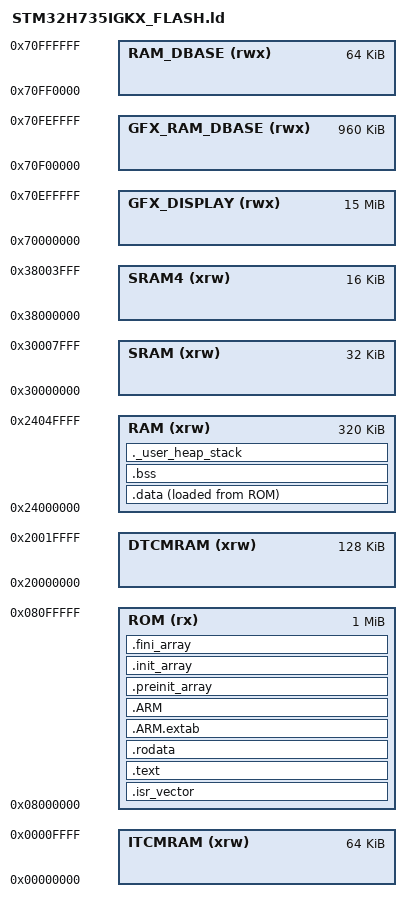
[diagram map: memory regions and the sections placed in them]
/**
 ******************************************************************************
 * @file      LinkerScript.ld
 * @author    Auto-generated by STM32CubeIDE
 *  Abstract    : Linker script for STM32H735G-DK Board embedding STM32H735IGKx Device from stm32h7 series
 *                      1024Kbytes ROM
 *                      64Kbytes ITCMRAM
 *                      128Kbytes RAM
 *
 *            Set heap size, stack size and stack location according
 *            to application requirements.
 *
 *            Set memory bank area and size if external memory is used
 ******************************************************************************
 * @attention
 *
 * Copyright (c) 2020 STMicroelectronics.
 * All rights reserved.
 *
 * This software is licensed under terms that can be found in the LICENSE file
 * in the root directory of this software component.
 * If no LICENSE file comes with this software, it is provided AS-IS.
 *
 ******************************************************************************
 */

/* Entry Point */
ENTRY(Reset_Handler)

/* Generate a link error if heap and stack don't fit into RAM */

_Min_Heap_Size  = __HEAP_SIZE;    /* required amount of heap  */
_Min_Stack_Size = __STACK_SIZE;   /* required amount of stack */

/* Specify the memory areas */
MEMORY
{
    ROM              (rx)  : ORIGIN = 0x08000000, LENGTH = 1024K
    ITCMRAM          (xrw) : ORIGIN = 0x00000000, LENGTH = 64K
    DTCMRAM          (xrw) : ORIGIN = 0x20000000, LENGTH = 128K
    RAM              (xrw) : ORIGIN = 0x24000000, LENGTH = 320K             /* Combine AXI SRAM and RAM Shared ITCM and AXI */
    SRAM             (xrw) : ORIGIN = 0x30000000, LENGTH = 32K              /* Combine SRAM1 and SRAM2 */
    SRAM4            (xrw) : ORIGIN = 0x38000000, LENGTH = 16K
    GFX_DISPLAY      (rwx) : ORIGIN = 0x70000000, LENGTH = 15M
    GFX_RAM_DBASE    (rwx) : ORIGIN = ORIGIN(GFX_DISPLAY) + LENGTH(GFX_DISPLAY), LENGTH = 1M - 64K
    RAM_DBASE        (rwx) : ORIGIN = ORIGIN(GFX_RAM_DBASE) + LENGTH(GFX_RAM_DBASE), LENGTH = 64K
}

/* Highest address of the user mode stack */
_estack = ORIGIN(RAM) + LENGTH(RAM);
_StackBottom = _estack - __STACK_SIZE;

/* Define output sections */
SECTIONS
{
  /* The startup code goes first into ROM */
  .isr_vector :
  {
    . = ALIGN(4);
    KEEP(*(.isr_vector)) /* Startup code */
    . = ALIGN(4);
  } >ROM

  /* The program code and other data into "ROM" Rom type memory */
  .text :
  {
    . = ALIGN(4);
    *(.text)           /* .text sections (code) */
    *(.text*)          /* .text* sections (code) */
    *(.glue_7)         /* glue arm to thumb code */
    *(.glue_7t)        /* glue thumb to arm code */
    *(.eh_frame)

    KEEP (*(.init))
    KEEP (*(.fini))

    . = ALIGN(4);
    _etext = .;        /* define a global symbols at end of code */
  } >ROM

  /* Constant data into "ROM" Rom type memory */
  .rodata :
  {
    . = ALIGN(4);
    *(.rodata)         /* .rodata sections (constants, strings, etc.) */
    *(.rodata*)        /* .rodata* sections (constants, strings, etc.) */
    . = ALIGN(4);
  } >ROM

  .ARM.extab :
  {
    . = ALIGN(4);
    *(.ARM.extab* .gnu.linkonce.armextab.*)
    . = ALIGN(4);
  } >ROM

  .ARM :
  {
    . = ALIGN(4);
    __exidx_start = .;
    *(.ARM.exidx*)
    __exidx_end = .;
    . = ALIGN(4);
  } >ROM

  .preinit_array :
  {
    . = ALIGN(4);
    PROVIDE_HIDDEN (__preinit_array_start = .);
    KEEP (*(.preinit_array*))
    PROVIDE_HIDDEN (__preinit_array_end = .);
    . = ALIGN(4);
  } >ROM

  .init_array :
  {
    . = ALIGN(4);
    PROVIDE_HIDDEN (__init_array_start = .);
    KEEP (*(SORT(.init_array.*)))
    KEEP (*(.init_array*))
    PROVIDE_HIDDEN (__init_array_end = .);
    . = ALIGN(4);
  } >ROM

  .fini_array :
  {
    . = ALIGN(4);
    PROVIDE_HIDDEN (__fini_array_start = .);
    KEEP (*(SORT(.fini_array.*)))
    KEEP (*(.fini_array*))
    PROVIDE_HIDDEN (__fini_array_end = .);
    . = ALIGN(4);
  } >ROM

  /* Used by the startup to initialize data */
  _sidata = LOADADDR(.data);

  /* Initialized data sections into "RAM" Ram type memory */
  .data :
  {
    . = ALIGN(4);
    _sdata = .;        /* create a global symbol at data start */
    *(.data)           /* .data sections */
    *(.data*)          /* .data* sections */

    . = ALIGN(4);
    _edata = .;        /* define a global symbol at data end */

  } >RAM AT> ROM

  /* Uninitialized data section into "RAM" Ram type memory */
  . = ALIGN(4);
  .bss :
  {
    /* This is used by the startup in order to initialize the .bss section */
    _sbss = .;         /* define a global symbol at bss start */
    __bss_start__ = _sbss;
    *(.bss)
    *(.bss*)
    *(COMMON)

    . = ALIGN(4);
    _ebss = .;         /* define a global symbol at bss end */
    __bss_end__ = _ebss;
  } >RAM

  /* User_heap_stack section, used to check that there is enough "RAM" Ram  type memory left */
  ._user_heap_stack :
  {
    . = ALIGN(8);
    PROVIDE ( end = . );
    PROVIDE ( _end = . );
    . = . + _Min_Heap_Size;
    . = . + _Min_Stack_Size;
    __HeapLimit = .;
    . = ALIGN(8);
  } >RAM

  /* Remove information from the compiler libraries */
  /DISCARD/ :
  {
    libc.a ( * )
    libm.a ( * )
    libgcc.a ( * )
  }

  .ARM.attributes 0 : { *(.ARM.attributes) }


    __StackLimit = _estack - _Min_Stack_Size;

    __gfx_display_base__   = ORIGIN(GFX_DISPLAY);
	__gfx_ram_data_base__  = ORIGIN(GFX_RAM_DBASE);
	__user_ram_data_base__ = ORIGIN(RAM_DBASE);

    /* Check if data + heap + stack exceeds RAM limit */
    ASSERT(__StackLimit >= __HeapLimit, "Region RAM overflowed with stack")

}
